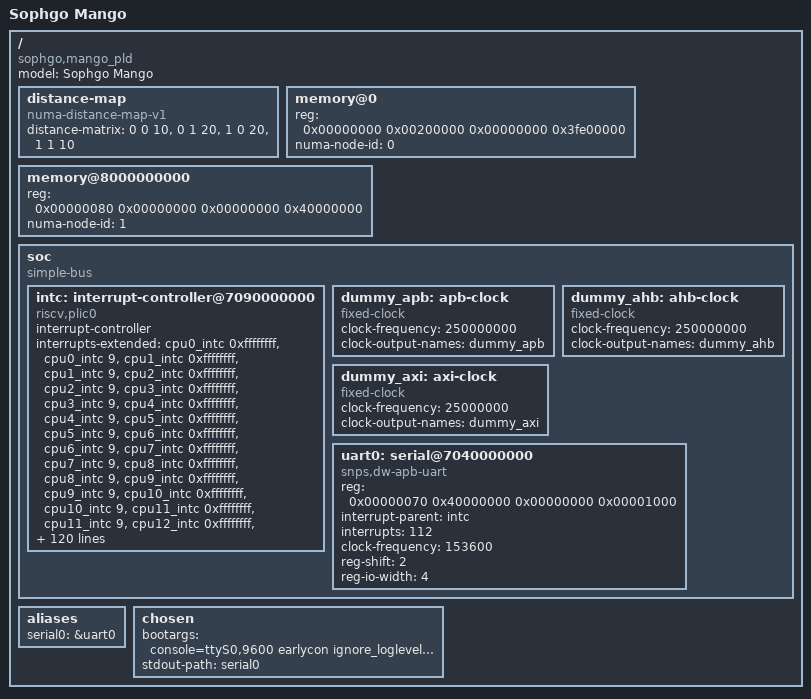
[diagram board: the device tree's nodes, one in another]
/dts-v1/;

#include "mango_socket0_cpus.dtsi"
#include "mango_socket1_cpus.dtsi"

/ {
	model = "Sophgo Mango";
	compatible = "sophgo,mango_pld";
	#address-cells = <2>;
	#size-cells = <2>;

	distance-map {
		compatible = "numa-distance-map-v1";
		distance-matrix = <0 0 10>,
				  <0 1 20>,
				  <1 0 20>,
				  <1 1 10>;
	};

	memory@0 {
		device_type = "memory";
		reg = <0x00000000 0x00200000 0x00000000 0x3fe00000>;
		numa-node-id = <0>;
	};
	memory@8000000000 {
		device_type = "memory";
		reg = <0x00000080 0x00000000 0x00000000 0x40000000>;
		numa-node-id = <1>;
	};

	soc {
		#address-cells = <2>;
		#size-cells = <2>;
		compatible = "simple-bus";
		ranges;

		intc: interrupt-controller@7090000000 {
			#interrupt-cells = <1>;
			compatible = "riscv,plic0";
			interrupt-controller;
			interrupts-extended = <
				&cpu0_intc  0xffffffff &cpu0_intc  9
				&cpu1_intc  0xffffffff &cpu1_intc  9
				&cpu2_intc  0xffffffff &cpu2_intc  9
				&cpu3_intc  0xffffffff &cpu3_intc  9
				&cpu4_intc  0xffffffff &cpu4_intc  9
				&cpu5_intc  0xffffffff &cpu5_intc  9
				&cpu6_intc  0xffffffff &cpu6_intc  9
				&cpu7_intc  0xffffffff &cpu7_intc  9
				&cpu8_intc  0xffffffff &cpu8_intc  9
				&cpu9_intc  0xffffffff &cpu9_intc  9
				&cpu10_intc  0xffffffff &cpu10_intc  9
				&cpu11_intc  0xffffffff &cpu11_intc  9
				&cpu12_intc  0xffffffff &cpu12_intc  9
				&cpu13_intc  0xffffffff &cpu13_intc  9
				&cpu14_intc  0xffffffff &cpu14_intc  9
				&cpu15_intc  0xffffffff &cpu15_intc  9
				&cpu16_intc  0xffffffff &cpu16_intc  9
				&cpu17_intc  0xffffffff &cpu17_intc  9
				&cpu18_intc  0xffffffff &cpu18_intc  9
				&cpu19_intc  0xffffffff &cpu19_intc  9
				&cpu20_intc  0xffffffff &cpu20_intc  9
				&cpu21_intc  0xffffffff &cpu21_intc  9
				&cpu22_intc  0xffffffff &cpu22_intc  9
				&cpu23_intc  0xffffffff &cpu23_intc  9
				&cpu24_intc  0xffffffff &cpu24_intc  9
				&cpu25_intc  0xffffffff &cpu25_intc  9
				&cpu26_intc  0xffffffff &cpu26_intc  9
				&cpu27_intc  0xffffffff &cpu27_intc  9
				&cpu28_intc  0xffffffff &cpu28_intc  9
				&cpu29_intc  0xffffffff &cpu29_intc  9
				&cpu30_intc  0xffffffff &cpu30_intc  9
				&cpu31_intc  0xffffffff &cpu31_intc  9
				&cpu32_intc  0xffffffff &cpu32_intc  9
				&cpu33_intc  0xffffffff &cpu33_intc  9
				&cpu34_intc  0xffffffff &cpu34_intc  9
				&cpu35_intc  0xffffffff &cpu35_intc  9
				&cpu36_intc  0xffffffff &cpu36_intc  9
				&cpu37_intc  0xffffffff &cpu37_intc  9
				&cpu38_intc  0xffffffff &cpu38_intc  9
				&cpu39_intc  0xffffffff &cpu39_intc  9
				&cpu40_intc  0xffffffff &cpu40_intc  9
				&cpu41_intc  0xffffffff &cpu41_intc  9
				&cpu42_intc  0xffffffff &cpu42_intc  9
				&cpu43_intc  0xffffffff &cpu43_intc  9
				&cpu44_intc  0xffffffff &cpu44_intc  9
				&cpu45_intc  0xffffffff &cpu45_intc  9
				&cpu46_intc  0xffffffff &cpu46_intc  9
				&cpu47_intc  0xffffffff &cpu47_intc  9
				&cpu48_intc  0xffffffff &cpu48_intc  9
				&cpu49_intc  0xffffffff &cpu49_intc  9
				&cpu50_intc  0xffffffff &cpu50_intc  9
				&cpu51_intc  0xffffffff &cpu51_intc  9
				&cpu52_intc  0xffffffff &cpu52_intc  9
				&cpu53_intc  0xffffffff &cpu53_intc  9
				&cpu54_intc  0xffffffff &cpu54_intc  9
				&cpu55_intc  0xffffffff &cpu55_intc  9
				&cpu56_intc  0xffffffff &cpu56_intc  9
				&cpu57_intc  0xffffffff &cpu57_intc  9
				&cpu58_intc  0xffffffff &cpu58_intc  9
				&cpu59_intc  0xffffffff &cpu59_intc  9
				&cpu60_intc  0xffffffff &cpu60_intc  9
				&cpu61_intc  0xffffffff &cpu61_intc  9
				&cpu62_intc  0xffffffff &cpu62_intc  9
				&cpu63_intc  0xffffffff &cpu63_intc  9

				//chip 1
				&cpu64_intc  0xffffffff &cpu64_intc  9
				&cpu65_intc  0xffffffff &cpu65_intc  9
				&cpu66_intc  0xffffffff &cpu66_intc  9
				&cpu67_intc  0xffffffff &cpu67_intc  9
				&cpu68_intc  0xffffffff &cpu68_intc  9
				&cpu69_intc  0xffffffff &cpu69_intc  9
				&cpu70_intc  0xffffffff &cpu70_intc  9
				&cpu71_intc  0xffffffff &cpu71_intc  9
				&cpu72_intc  0xffffffff &cpu72_intc  9
				&cpu73_intc  0xffffffff &cpu73_intc  9
				&cpu74_intc  0xffffffff &cpu74_intc  9
				&cpu75_intc  0xffffffff &cpu75_intc  9
				&cpu76_intc  0xffffffff &cpu76_intc  9
				&cpu77_intc  0xffffffff &cpu77_intc  9
				&cpu78_intc  0xffffffff &cpu78_intc  9
				&cpu79_intc  0xffffffff &cpu79_intc  9
				&cpu80_intc  0xffffffff &cpu80_intc  9
				&cpu81_intc  0xffffffff &cpu81_intc  9
				&cpu82_intc  0xffffffff &cpu82_intc  9
				&cpu83_intc  0xffffffff &cpu83_intc  9
				&cpu84_intc  0xffffffff &cpu84_intc  9
				&cpu85_intc  0xffffffff &cpu85_intc  9
				&cpu86_intc  0xffffffff &cpu86_intc  9
				&cpu87_intc  0xffffffff &cpu87_intc  9
				&cpu88_intc  0xffffffff &cpu88_intc  9
				&cpu89_intc  0xffffffff &cpu89_intc  9
				&cpu90_intc  0xffffffff &cpu90_intc  9
				&cpu91_intc  0xffffffff &cpu91_intc  9
				&cpu92_intc  0xffffffff &cpu92_intc  9
				&cpu93_intc  0xffffffff &cpu93_intc  9
				&cpu94_intc  0xffffffff &cpu94_intc  9
				&cpu95_intc  0xffffffff &cpu95_intc  9
				&cpu96_intc  0xffffffff &cpu96_intc  9
				&cpu97_intc  0xffffffff &cpu97_intc  9
				&cpu98_intc  0xffffffff &cpu98_intc  9
				&cpu99_intc  0xffffffff &cpu99_intc  9
				&cpu100_intc  0xffffffff &cpu100_intc  9
				&cpu101_intc  0xffffffff &cpu101_intc  9
				&cpu102_intc  0xffffffff &cpu102_intc  9
				&cpu103_intc  0xffffffff &cpu103_intc  9
				&cpu104_intc  0xffffffff &cpu104_intc  9
				&cpu105_intc  0xffffffff &cpu105_intc  9
				&cpu106_intc  0xffffffff &cpu106_intc  9
				&cpu107_intc  0xffffffff &cpu107_intc  9
				&cpu108_intc  0xffffffff &cpu108_intc  9
				&cpu109_intc  0xffffffff &cpu109_intc  9
				&cpu110_intc  0xffffffff &cpu110_intc  9
				&cpu111_intc  0xffffffff &cpu111_intc  9
				&cpu112_intc  0xffffffff &cpu112_intc  9
				&cpu113_intc  0xffffffff &cpu113_intc  9
				&cpu114_intc  0xffffffff &cpu114_intc  9
				&cpu115_intc  0xffffffff &cpu115_intc  9
				&cpu116_intc  0xffffffff &cpu116_intc  9
				&cpu117_intc  0xffffffff &cpu117_intc  9
				&cpu118_intc  0xffffffff &cpu118_intc  9
				&cpu119_intc  0xffffffff &cpu119_intc  9
				&cpu120_intc  0xffffffff &cpu120_intc  9
				&cpu121_intc  0xffffffff &cpu121_intc  9
				&cpu122_intc  0xffffffff &cpu122_intc  9
				&cpu123_intc  0xffffffff &cpu123_intc  9
				&cpu124_intc  0xffffffff &cpu124_intc  9
				&cpu125_intc  0xffffffff &cpu125_intc  9
				&cpu126_intc  0xffffffff &cpu126_intc  9
				&cpu127_intc  0xffffffff &cpu127_intc  9
				>;
			reg = <0x00000070 0x90000000 0x00000000 0x04000000>;
			reg-names = "control";
			riscv,max-priority = <7>;
			riscv,ndev = <172>;
		};

		dummy_apb: apb-clock {
			compatible = "fixed-clock";
			clock-frequency = <250000000>;
			clock-output-names = "dummy_apb";
			#clock-cells = <0>;
		};

		dummy_ahb: ahb-clock {
			compatible = "fixed-clock";
			clock-frequency = <250000000>;
			clock-output-names = "dummy_ahb";
			#clock-cells = <0>;
		};

		dummy_axi: axi-clock {
			compatible = "fixed-clock";
			clock-frequency = <25000000>;
			clock-output-names = "dummy_axi";
			#clock-cells = <0>;
		};

		uart0: serial@7040000000 {
			compatible = "snps,dw-apb-uart";
			reg = <0x00000070 0x40000000 0x00000000 0x00001000>;
			interrupt-parent = <&intc>;
			interrupts = <112>;
			clock-frequency = <153600>;
			clock-names = "baudclk";
			reg-shift = <2>;
			reg-io-width = <4>;
		};
	};

#if 0
	pcie@7060000000 {
		compatible = "sophgo,cdns-pcie-host";
		device_type = "pci";
		#address-cells = <3>;
		#size-cells = <2>;

		bus-range = <0x0 0xff>;
		linux,pci-domain = <0>;
		cdns,max-outbound-regions = <16>;
		cdns,no-bar-match-nbits = <48>;
		vendor-id = /bits/ 16 <0x1E30>;
		device-id = /bits/ 16 <0x2042>;
		interrupt-parent = <&intc>;
		interrupts = <122>;
		interrupt-names = "msi";
		reg = <0x70 0x60000000  0x0 0x02000000>,
		    <0x40 0x00000000  0x0 0x00001000>;
		reg-names = "reg", "cfg";

		// IO, check IO_SPACE_LIMIT
		// 64bit non-prefetchable memory
		ranges = <0x01000000 0x0 0x10000000  0x40 0x10000000  0x0 0x01000000>,
		       <0x03000000 0x0 0x20000000  0x40 0x20000000  0x0 0x10000000>;

		status = "okay";
	};
#endif

	aliases {
		serial0 = &uart0;
	};

	chosen {
		/* bootargs = "console=ttyS0,115200 crashkernel=256M-:128M manGo_mmu_v1"; */
		/* linux,initrd-start = <0x2000000>; */
		/* linux,initrd-end = <0x17000000>; */
		bootargs = "console=ttyS0,9600 earlycon ignore_loglevel rdinit=/init root=/dev/ram0 rw \
initrd=0x30000000,32M retain_initrd";
		stdout-path = "serial0";
	};
};
